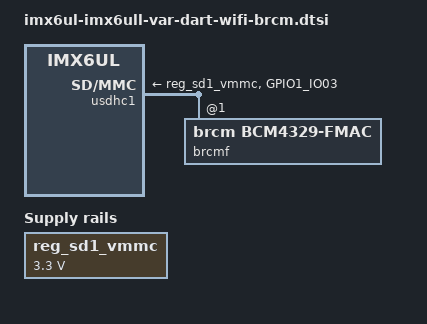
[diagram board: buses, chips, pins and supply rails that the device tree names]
/*
 * Copyright (C) 2015-2025 Variscite Ltd. - https://www.variscite.com
 *
 * This program is free software; you can redistribute it and/or modify
 * it under the terms of the GNU General Public License version 2 as
 * published by the Free Software Foundation.
 */

/ {
	regulators {
		reg_sd1_vmmc: regulator_sd1_vmmc {
			compatible = "regulator-fixed";
			regulator-name = "VSD_3V3";
			regulator-min-microvolt = <3300000>;
			regulator-max-microvolt = <3300000>;
		};
	};
};

&iomuxc {
	pinctrl_32k_clk: 32kclkgrp {
		fsl,pins = <
			MX6UL_PAD_GPIO1_IO03__OSC32K_32K_OUT	0x03029
		>;
	};
};

&tsc {
	status = "disabled";
};

&usdhc1 {
	#address-cells = <1>;
	#size-cells = <0>;
	pinctrl-names = "default", "state_100mhz", "state_200mhz";
	pinctrl-0 = <&pinctrl_usdhc1>, <&pinctrl_32k_clk>, <&pinctrl_wifi>;
	pinctrl-1 = <&pinctrl_usdhc1_100mhz>, <&pinctrl_32k_clk>, <&pinctrl_wifi>;
	pinctrl-2 = <&pinctrl_usdhc1_200mhz>, <&pinctrl_32k_clk>, <&pinctrl_wifi>;
	keep-power-in-suspend;
	vmmc-supply = <&reg_sd1_vmmc>;
	status = "okay";

	brcmf: bcrmf@1 {
		reg = <1>;
		compatible = "brcm,bcm4329-fmac";
	};
};
